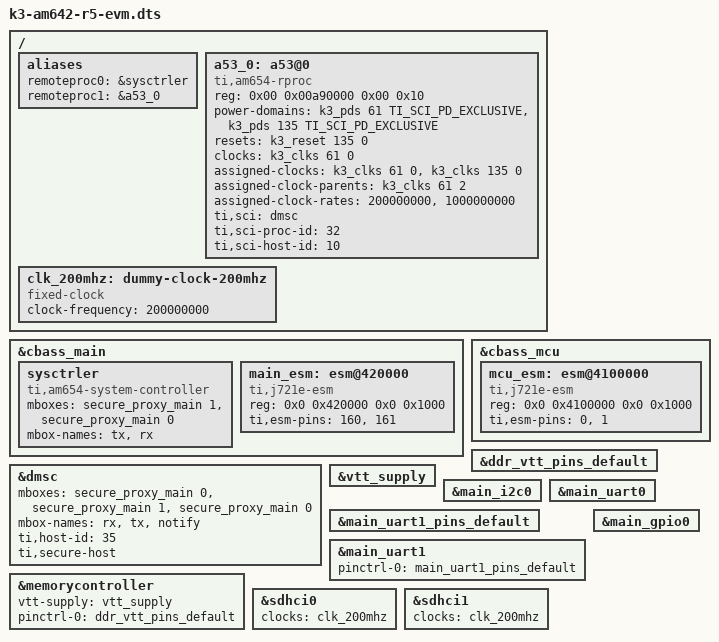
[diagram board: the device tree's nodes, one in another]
// SPDX-License-Identifier: GPL-2.0
/*
 * Copyright (C) 2020-2021 Texas Instruments Incorporated - https://www.ti.com/
 */

/dts-v1/;

#include "k3-am642-evm.dts"
#include "k3-am64-evm-ddr4-1600MTs.dtsi"
#include "k3-am64-ddr.dtsi"

#include "k3-am642-evm-u-boot.dtsi"

/ {
	aliases {
		remoteproc0 = &sysctrler;
		remoteproc1 = &a53_0;
	};

	a53_0: a53@0 {
		compatible = "ti,am654-rproc";
		reg = <0x00 0x00a90000 0x00 0x10>;
		power-domains = <&k3_pds 61 TI_SCI_PD_EXCLUSIVE>,
				<&k3_pds 135 TI_SCI_PD_EXCLUSIVE>;
		resets = <&k3_reset 135 0>;
		clocks = <&k3_clks 61 0>;
		assigned-clocks = <&k3_clks 61 0>, <&k3_clks 135 0>;
		assigned-clock-parents = <&k3_clks 61 2>;
		assigned-clock-rates = <200000000>, <1000000000>;
		ti,sci = <&dmsc>;
		ti,sci-proc-id = <32>;
		ti,sci-host-id = <10>;
		bootph-pre-ram;
	};

	clk_200mhz: dummy-clock-200mhz {
		compatible = "fixed-clock";
		#clock-cells = <0>;
		clock-frequency = <200000000>;
		bootph-pre-ram;
	};
};

&cbass_main {
	sysctrler: sysctrler {
		compatible = "ti,am654-system-controller";
		mboxes= <&secure_proxy_main 1>, <&secure_proxy_main 0>;
		mbox-names = "tx", "rx";
		bootph-pre-ram;
	};

	/* XXX: Upstream kernel TODO: send upstream */
	main_esm: esm@420000 {
		compatible = "ti,j721e-esm";
		reg = <0x0 0x420000 0x0 0x1000>;
		ti,esm-pins = <160>, <161>;
		bootph-pre-ram;
	};
};

&cbass_mcu {
	bootph-pre-ram;

	/* XXX: Upstream kernel TODO: send upstream */
	mcu_esm: esm@4100000 {
		compatible = "ti,j721e-esm";
		reg = <0x0 0x4100000 0x0 0x1000>;
		ti,esm-pins = <0>, <1>;
		bootph-pre-ram;
	};
};

&dmsc {
	bootph-pre-ram;
	mboxes= <&secure_proxy_main 0>,
		<&secure_proxy_main 1>,
		<&secure_proxy_main 0>;
	mbox-names = "rx", "tx", "notify";
	ti,host-id = <35>;
	ti,secure-host;
};

&ddr_vtt_pins_default {
	bootph-pre-ram;
};

&vtt_supply {
	bootph-pre-ram;
};

/* EEPROM might be read before SYSFW is available */
&main_i2c0 {
	/delete-property/ power-domains;
};

&main_uart0 {
	/* Clocked by default */
	/delete-property/ power-domains;
	/delete-property/ clocks;
	/delete-property/ clock-names;
};

&main_uart1_pins_default {
	bootph-pre-ram;
};

&main_uart1 {
	bootph-pre-ram;
	pinctrl-names = "default";
	pinctrl-0 = <&main_uart1_pins_default>;
	status = "okay";
};

&memorycontroller {
	vtt-supply = <&vtt_supply>;
	pinctrl-names = "default";
	pinctrl-0 = <&ddr_vtt_pins_default>;
};

&sdhci0 {
	/* Clocked by default */
	/delete-property/ power-domains;
	clocks = <&clk_200mhz>;
	clock-names = "clk_xin";
};

&sdhci1 {
	/* Clocked by default */
	/delete-property/ power-domains;
	clocks = <&clk_200mhz>;
	clock-names = "clk_xin";
};

&main_gpio0 {
	bootph-pre-ram;
	/* Clocked by default */
	/delete-property/ power-domains;
};
